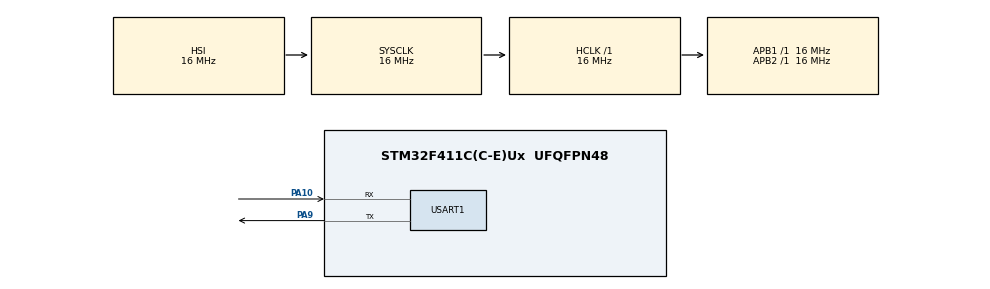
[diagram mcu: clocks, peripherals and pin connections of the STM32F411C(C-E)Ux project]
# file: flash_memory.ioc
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Mcu.Family=STM32F4
Mcu.Name=STM32F411C(C-E)Ux
Mcu.Package=UFQFPN48
NVIC.PriorityGroup=NVIC_PRIORITYGROUP_4
PA10.Mode=Asynchronous
PA10.Signal=USART1_RX
PA9.Mode=Asynchronous
PA9.Signal=USART1_TX
ProjectManager.HeapSize=0x200
ProjectManager.StackSize=0x400
ProjectManager.TargetToolchain=STM32CubeIDE
RCC.AHBFreq_Value=16000000
RCC.APB1Freq_Value=16000000
RCC.APB2Freq_Value=16000000
RCC.CortexFreq_Value=16000000
RCC.HSE_VALUE=25000000
RCC.HSI_VALUE=16000000
RCC.LSE_VALUE=32768
RCC.SYSCLKFreq_VALUE=16000000
RCC.VCOOutputFreq_Value=192000000
USART1.VirtualMode=VM_ASYNC
board=custom

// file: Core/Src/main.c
/* USER CODE BEGIN Header */
/**
  ******************************************************************************
  * @file           : main.c
  * @brief          : Main program body
  ******************************************************************************
  * @attention
  *
  * Copyright (c) 2024 STMicroelectronics.
  * All rights reserved.
  *
  * This software is licensed under terms that can be found in the LICENSE file
  * in the root directory of this software component.
  * If no LICENSE file comes with this software, it is provided AS-IS.
  *
  ******************************************************************************
  */
/* USER CODE END Header */
#include "main.h"

/* USER CODE BEGIN Includes */
#include <string.h>

/* USER CODE END Includes */

/* USER CODE BEGIN PD */
#define FLASH_USER_START_ADDR   0x08040000   // Alamat flash sektor 6
#define FLASH_STRING_ADDR       0x08040000   // Alamat untuk menulis string
#define FLASH_INTEGER_ADDR      0x08040080   // Alamat untuk menulis integer
#define FLASH_FLOAT_ADDR        0x08040090   // Alamat untuk menulis float

/* USER CODE END PD */

UART_HandleTypeDef huart1;

void SystemClock_Config(void);
static void MX_GPIO_Init(void);
static void MX_USART1_UART_Init(void);

/* USER CODE BEGIN 0 */
// Fungsi umum untuk menulis data ke flash
void Flash_Write(uint32_t address, void *data, uint32_t length)
{
    HAL_FLASH_Unlock();
    for (uint32_t i = 0; i < length; i += 4)
    {
        uint32_t data_word;
        memcpy(&data_word, (uint8_t*)data + i, (length - i) < 4 ? (length - i) : 4);
        HAL_FLASH_Program(FLASH_TYPEPROGRAM_WORD, address + i, data_word);
    }
    HAL_FLASH_Lock();
}

// Fungsi umum untuk membaca data dari flash
void Flash_Read(uint32_t address, void *buffer, uint32_t length)
{
    memcpy(buffer, (uint8_t*)address, length);
}

// Fungsi untuk menghapus sektor flash
void Flash_Erase_Sector(uint32_t sector)
{
    HAL_FLASH_Unlock();
    FLASH_EraseInitTypeDef eraseInitStruct = {0};
    uint32_t pageError = 0;

    eraseInitStruct.TypeErase = FLASH_TYPEERASE_SECTORS;
    eraseInitStruct.Sector = sector;
    eraseInitStruct.NbSectors = 1;
    eraseInitStruct.VoltageRange = FLASH_VOLTAGE_RANGE_3;

    HAL_FLASHEx_Erase(&eraseInitStruct, &pageError);
    HAL_FLASH_Lock();
}

// Fungsi delay
void delay_ms(uint32_t ms)
{
    HAL_Delay(ms);
}
/* USER CODE END 0 */

int main(void)
{

  /* MCU Configuration--------------------------------------------------------*/

  /* Reset of all peripherals, Initializes the Flash interface and the Systick. */
  HAL_Init();

  /* Configure the system clock */
  SystemClock_Config();

  /* Initialize all configured peripherals */
  MX_GPIO_Init();
  MX_USART1_UART_Init();
  /* USER CODE BEGIN 2 */
  // Data yang akan ditulis
  char string_to_write[] = "BISMILLAHIRRAHMANIRRAHIM";
  int32_t int_value = 12345;
  float float_value = 123.456f;

  // Menghapus flash sebelum menulis (hapus sektor 6)
  Flash_Erase_Sector(FLASH_SECTOR_6);

  // Menulis data ke flash
  Flash_Write(FLASH_STRING_ADDR, string_to_write, strlen(string_to_write) + 1); // Tulis string
  Flash_Write(FLASH_INTEGER_ADDR, &int_value, sizeof(int32_t)); // Tulis integer
  Flash_Write(FLASH_FLOAT_ADDR, &float_value, sizeof(float));   // Tulis float

  // Membaca data kembali dari flash
  char string_buffer[50];
  int32_t read_int;
  float read_float;

  Flash_Read(FLASH_STRING_ADDR, string_buffer, sizeof(string_buffer)); // Baca string
  Flash_Read(FLASH_INTEGER_ADDR, &read_int, sizeof(read_int));         // Baca integer
  Flash_Read(FLASH_FLOAT_ADDR, &read_float, sizeof(read_float));       // Baca float

//  // Menghapus flash sebelum menulis (hapus sektor 6)
//  Flash_Erase_Sector(FLASH_SECTOR_6);

  /* USER CODE END 2 */

  /* Infinite loop */
  while (1)
  {

  }
}

void SystemClock_Config(void)
{
  RCC_OscInitTypeDef RCC_OscInitStruct = {0};
  RCC_ClkInitTypeDef RCC_ClkInitStruct = {0};

  /** Configure the main internal regulator output voltage
  */
  __HAL_RCC_PWR_CLK_ENABLE();
  __HAL_PWR_VOLTAGESCALING_CONFIG(PWR_REGULATOR_VOLTAGE_SCALE1);

  /** Initializes the RCC Oscillators according to the specified parameters
  * in the RCC_OscInitTypeDef structure.
  */
  RCC_OscInitStruct.OscillatorType = RCC_OSCILLATORTYPE_HSI;
  RCC_OscInitStruct.HSIState = RCC_HSI_ON;
  RCC_OscInitStruct.HSICalibrationValue = RCC_HSICALIBRATION_DEFAULT;
  RCC_OscInitStruct.PLL.PLLState = RCC_PLL_NONE;
  if (HAL_RCC_OscConfig(&RCC_OscInitStruct) != HAL_OK)
  {
    Error_Handler();
  }

  /** Initializes the CPU, AHB and APB buses clocks
  */
  RCC_ClkInitStruct.ClockType = RCC_CLOCKTYPE_HCLK|RCC_CLOCKTYPE_SYSCLK
                              |RCC_CLOCKTYPE_PCLK1|RCC_CLOCKTYPE_PCLK2;
  RCC_ClkInitStruct.SYSCLKSource = RCC_SYSCLKSOURCE_HSI;
  RCC_ClkInitStruct.AHBCLKDivider = RCC_SYSCLK_DIV1;
  RCC_ClkInitStruct.APB1CLKDivider = RCC_HCLK_DIV1;
  RCC_ClkInitStruct.APB2CLKDivider = RCC_HCLK_DIV1;

  if (HAL_RCC_ClockConfig(&RCC_ClkInitStruct, FLASH_LATENCY_0) != HAL_OK)
  {
    Error_Handler();
  }
}

static void MX_USART1_UART_Init(void)
{

  huart1.Instance = USART1;
  huart1.Init.BaudRate = 115200;
  huart1.Init.WordLength = UART_WORDLENGTH_8B;
  huart1.Init.StopBits = UART_STOPBITS_1;
  huart1.Init.Parity = UART_PARITY_NONE;
  huart1.Init.Mode = UART_MODE_TX_RX;
  huart1.Init.HwFlowCtl = UART_HWCONTROL_NONE;
  huart1.Init.OverSampling = UART_OVERSAMPLING_16;
  if (HAL_UART_Init(&huart1) != HAL_OK)
  {
    Error_Handler();
  }

}

static void MX_GPIO_Init(void)
{

  /* GPIO Ports Clock Enable */
  __HAL_RCC_GPIOA_CLK_ENABLE();

}

void Error_Handler(void)
{
  __disable_irq();
  while (1)
  {
  }
}
